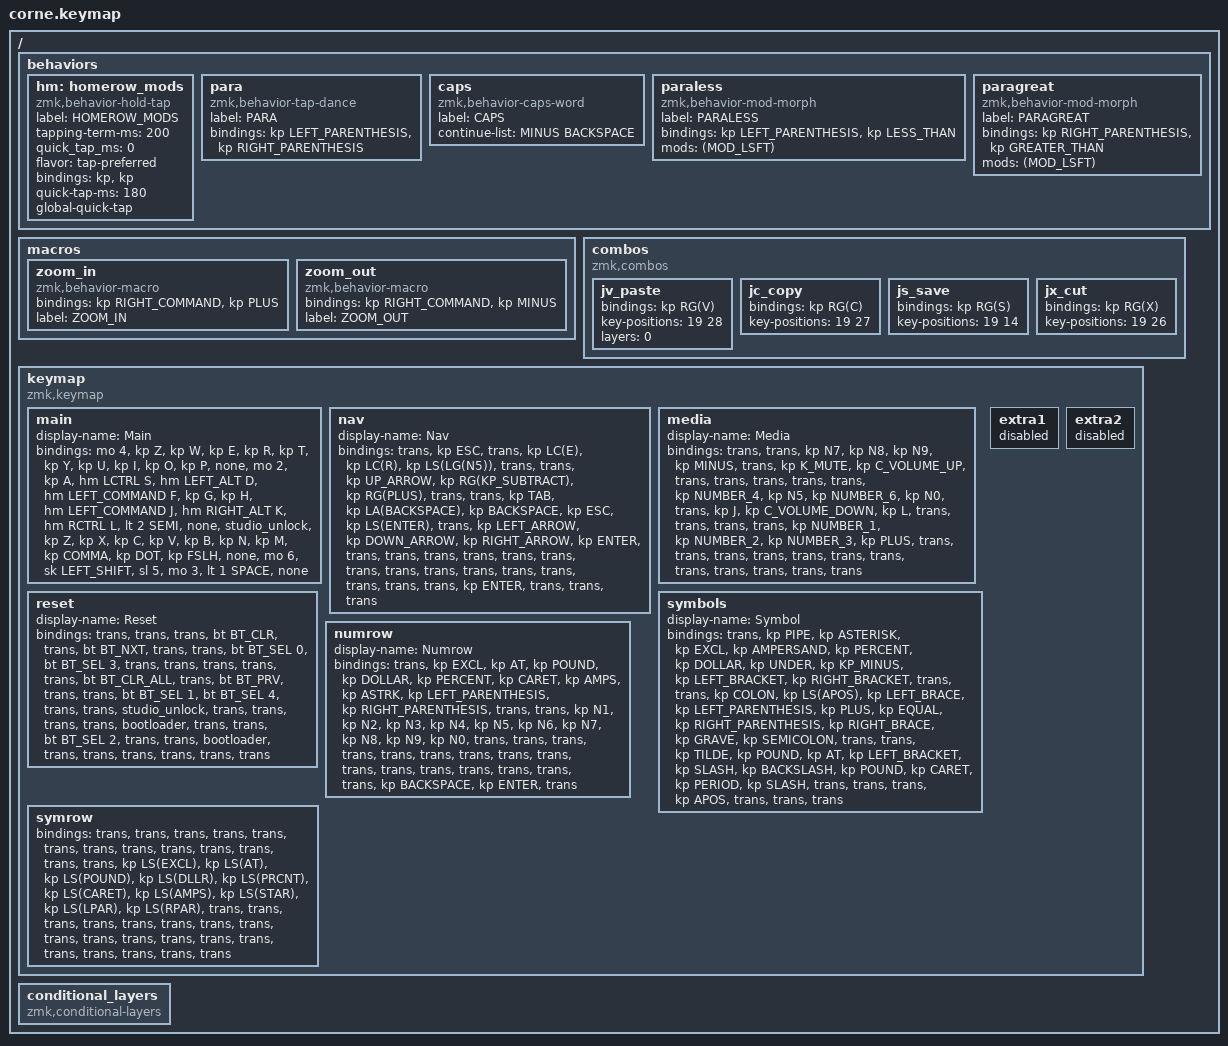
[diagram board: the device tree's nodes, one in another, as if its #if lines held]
#include <behaviors.dtsi>
#include <dt-bindings/zmk/bt.h>
#include <dt-bindings/zmk/keys.h>

/ {
    behaviors {
        hm: homerow_mods {
            compatible = "zmk,behavior-hold-tap";
            label = "HOMEROW_MODS";
            #binding-cells = <2>;
            tapping-term-ms = <200>;
            quick_tap_ms = <0>;
            flavor = "tap-preferred";
            bindings = <&kp>, <&kp>;

            quick-tap-ms = <180>;
            global-quick-tap;
        };

        para: para {
            compatible = "zmk,behavior-tap-dance";
            label = "PARA";
            #binding-cells = <0>;
            bindings = <&kp LEFT_PARENTHESIS>, <&kp RIGHT_PARENTHESIS>;
        };

        caps: caps {
            compatible = "zmk,behavior-caps-word";
            label = "CAPS";
            #binding-cells = <0>;
            continue-list = <MINUS BACKSPACE>;
        };

        paraless: paraless {
            compatible = "zmk,behavior-mod-morph";
            label = "PARALESS";
            bindings = <&kp LEFT_PARENTHESIS>, <&kp LESS_THAN>;

            #binding-cells = <0>;
            mods = <(MOD_LSFT)>;
        };

        paragreat: paragreat {
            compatible = "zmk,behavior-mod-morph";
            label = "PARAGREAT";
            bindings = <&kp RIGHT_PARENTHESIS>, <&kp GREATER_THAN>;

            #binding-cells = <0>;
            mods = <(MOD_LSFT)>;
        };
    };

    macros {
        zoom_in: zoom_in {
            compatible = "zmk,behavior-macro";
            #binding-cells = <0>;
            bindings = <&kp RIGHT_COMMAND &kp PLUS>;
            label = "ZOOM_IN";
        };

        zoom_out: zoom_out {
            compatible = "zmk,behavior-macro";
            #binding-cells = <0>;
            bindings = <&kp RIGHT_COMMAND &kp MINUS>;
            label = "ZOOM_OUT";
        };
    };

    combos {
        compatible = "zmk,combos";

        jv_paste {
            bindings = <&kp RG(V)>;
            key-positions = <19 28>;
            layers = <0>;
        };

        jc_copy {
            bindings = <&kp RG(C)>;
            key-positions = <19 27>;
        };

        js_save {
            bindings = <&kp RG(S)>;
            key-positions = <19 14>;
        };

        jx_cut {
            bindings = <&kp RG(X)>;
            key-positions = <19 26>;
        };
    };

    //

    keymap {
        compatible = "zmk,keymap";

        main {
            display-name = "Main";

            // -----------------------------------------------------------------------------------------
            // |  Q  |  W  |  E  |  R  |  T  |   |  Y  |  U   |  I  |  O  |  P  |
            // |  A  |  S  |  D  |  F  |  G  |   |  H  |  J   |  K  |  L  |  ;  |
            // |  Z  |  X  |  C  |  V  |  B  |   |  N  |  M   |  ,  |  .  |  /  |
            // | GUI | CTRL | SHFT | LWR | SPC |   | ENT | RSE  | BKSP | ALT | ESC |

            bindings = <
&mo 4           &kp Z  &kp W        &kp E           &kp R               &kp T    &kp Y  &kp U               &kp I            &kp O        &kp P       &none
&mo 2           &kp A  &hm LCTRL S  &hm LEFT_ALT D  &hm LEFT_COMMAND F  &kp G    &kp H  &hm LEFT_COMMAND J  &hm RIGHT_ALT K  &hm RCTRL L  &lt 2 SEMI  &none
&studio_unlock  &kp Z  &kp X        &kp C           &kp V               &kp B    &kp N  &kp M               &kp COMMA        &kp DOT      &kp FSLH    &none
                                    &mo 6           &sk LEFT_SHIFT      &sl 5    &mo 3  &lt 1 SPACE         &none
            >;
        };

        nav {
            display-name = "Nav";

            // -----------------------------------------------------------------------------------------
            // |  TAB |  1  |  2  |  3  |  4  |  5  |   |  6  |  7  |  8  |  9  |  0  | BKSP |
            // | BTCLR| BT1 | BT2 | BT3 | BT4 | BT5 |   | LFT | DWN |  UP | RGT |     |      |
            // | SHFT |     |     |     |     |     |   |     |     |     |     |     |      |
            // | GUI | CTRL | SHFT | LWR | SPC |   | ENT | RSE  | BKSP | ALT | ESC |

            bindings = <
&trans  &kp ESC  &trans             &kp LC(E)      &kp LC(R)  &kp LS(LG(N5))    &trans  &trans          &kp UP_ARROW    &kp RG(KP_SUBTRACT)  &kp RG(PLUS)  &trans
&trans  &kp TAB  &kp LA(BACKSPACE)  &kp BACKSPACE  &kp ESC    &kp LS(ENTER)     &trans  &kp LEFT_ARROW  &kp DOWN_ARROW  &kp RIGHT_ARROW      &kp ENTER     &trans
&trans  &trans   &trans             &trans         &trans     &trans            &trans  &trans          &trans          &trans               &trans        &trans
                                    &trans         &trans     &kp ENTER         &trans  &trans          &trans
            >;
        };

        media {
            display-name = "Media";

            // -----------------------------------------------------------------------------------------
            // |  TAB |  !  |  @  |  #  |  $  |  %  |   |  ^  |  &  |  *  |  (  |  )  | BKSP |
            // | CTRL |     |     |     |     |     |   |  -  |  =  |  [  |  ]  |  \  |  `   |
            // | SHFT |     |     |     |     |     |   |  _  |  +  |  {  |  }  | "|" |  ~   |
            //                    | GUI |     | SPC |   | ENT |     | ALT |

            bindings = <
&trans  &trans  &kp N7        &kp N8        &kp N9        &kp MINUS    &trans  &kp K_MUTE  &kp C_VOLUME_UP    &trans  &trans  &trans
&trans  &trans  &kp NUMBER_4  &kp N5        &kp NUMBER_6  &kp N0       &trans  &kp J       &kp C_VOLUME_DOWN  &kp L   &trans  &trans
&trans  &trans  &kp NUMBER_1  &kp NUMBER_2  &kp NUMBER_3  &kp PLUS     &trans  &trans      &trans             &trans  &trans  &trans
                              &trans        &trans        &trans       &trans  &trans      &trans
            >;
        };

        symbols {
            #ifdef KEYMAP_DRAWER
                display-name = "Symbol";
#else
                display-name = "Symbols";
#endif

            bindings = <
&trans  &kp PIPE   &kp ASTERISK  &kp EXCL        &kp AMPERSAND         &kp PERCENT    &kp DOLLAR     &kp UNDER              &kp KP_MINUS     &kp LEFT_BRACKET  &kp RIGHT_BRACKET  &trans
&trans  &kp COLON  &kp LS(APOS)  &kp LEFT_BRACE  &kp LEFT_PARENTHESIS  &kp PLUS       &kp EQUAL      &kp RIGHT_PARENTHESIS  &kp RIGHT_BRACE  &kp GRAVE         &kp SEMICOLON      &trans
&trans  &kp TILDE  &kp POUND     &kp AT          &kp LEFT_BRACKET      &kp SLASH      &kp BACKSLASH  &kp POUND              &kp CARET        &kp PERIOD        &kp SLASH          &trans
                                 &trans          &trans                &kp APOS       &trans         &trans                 &trans
            >;
        };

        reset {
            display-name = "Reset";
            bindings = <
&trans          &trans  &trans  &bt BT_CLR      &trans  &bt BT_NXT     &trans  &trans  &bt BT_SEL 0  &bt BT_SEL 3  &trans  &trans
&trans          &trans  &trans  &bt BT_CLR_ALL  &trans  &bt BT_PRV     &trans  &trans  &bt BT_SEL 1  &bt BT_SEL 4  &trans  &trans
&studio_unlock  &trans  &trans  &trans          &trans  &bootloader    &trans  &trans  &bt BT_SEL 2  &trans        &trans  &bootloader
                                &trans          &trans  &trans         &trans  &trans  &trans
            >;
        };

        numrow {
            display-name = "Numrow";
            bindings = <
&trans  &kp EXCL  &kp AT  &kp POUND  &kp DOLLAR  &kp PERCENT    &kp CARET      &kp AMPS   &kp ASTRK  &kp LEFT_PARENTHESIS  &kp RIGHT_PARENTHESIS  &trans
&trans  &kp N1    &kp N2  &kp N3     &kp N4      &kp N5         &kp N6         &kp N7     &kp N8     &kp N9                &kp N0                 &trans
&trans  &trans    &trans  &trans     &trans      &trans         &trans         &trans     &trans     &trans                &trans                 &trans
                          &trans     &trans      &trans         &kp BACKSPACE  &kp ENTER  &trans
            >;
        };

        symrow {
            bindings = <
&trans  &trans        &trans      &trans         &trans        &trans           &trans         &trans        &trans        &trans        &trans        &trans
&trans  &kp LS(EXCL)  &kp LS(AT)  &kp LS(POUND)  &kp LS(DLLR)  &kp LS(PRCNT)    &kp LS(CARET)  &kp LS(AMPS)  &kp LS(STAR)  &kp LS(LPAR)  &kp LS(RPAR)  &trans
&trans  &trans        &trans      &trans         &trans        &trans           &trans         &trans        &trans        &trans        &trans        &trans
                                  &trans         &trans        &trans           &trans         &trans        &trans
            >;
        };

        extra1 { status = "reserved"; };

        extra2 { status = "reserved"; };
    };

    conditional_layers { compatible = "zmk,conditional-layers"; };
};
